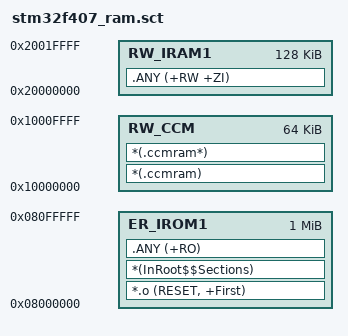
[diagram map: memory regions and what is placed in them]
; STM32F407VET6: 128KB SRAM @0x20000000 + 64KB CCM @0x10000000
; CCM must be listed before .ANY so .ccmram is not pulled into SRAM

LR_IROM1 0x08000000 0x00100000  {
  ER_IROM1 0x08000000 0x00100000  {
   *.o (RESET, +First)
   *(InRoot$$Sections)
   .ANY (+RO)
  }
  RW_CCM 0x10000000 0x00010000  {
   *(.ccmram)
   *(.ccmram*)
  }
  RW_IRAM1 0x20000000 0x00020000  {
   .ANY (+RW +ZI)
  }
}
